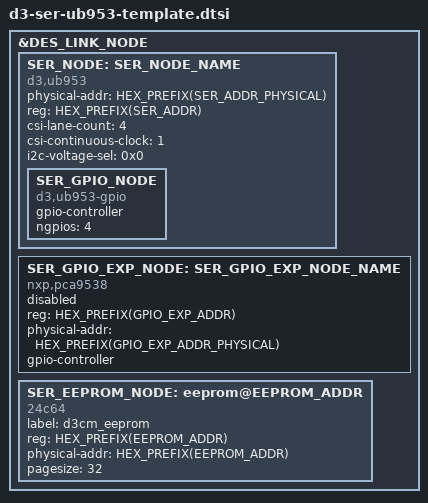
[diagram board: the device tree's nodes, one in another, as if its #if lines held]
/*
 * Copyright (c) 2019, D3 Engineering. All rights reserved.
 *
 * This program is free software; you can redistribute it and/or modify
 * it under the terms of the GNU General Public License as published by
 * the Free Software Foundation; version 2 of the License.
 *
 * This program is distributed in the hope that it will be useful, but WITHOUT
 * ANY WARRANTY; without even the implied warranty of MERCHANTABILITY or
 * FITNESS FOR A PARTICULAR PURPOSE.  See the GNU General Public License for
 * more details.
 */

#include "d3-reset-ser.dtsi"
#define SER_MODEL ub953
#define SER_ADDR_PHYSICAL 18
#define GPIO_EXP_ADDR_PHYSICAL 70
#include "d3-ser-common.dtsi"
#include "d3-check-ser-fpdlink.dtsi"

&DES_LINK_NODE {
	SER_NODE: SER_NODE_NAME {
		compatible = "d3,ub953";
		status = STR(STATUS);
		physical-addr = <HEX_PREFIX(SER_ADDR_PHYSICAL)>;
		#address-cells = <1>;
		#size-cells = <0>;
		reg = <HEX_PREFIX(SER_ADDR)>;
		csi-lane-count = <4>;
		csi-continuous-clock = <1>;
		i2c-voltage-sel = <0x0>;


		SER_GPIO_NODE: SER_GPIO_NODE {
			compatible = "d3,ub953-gpio";
			status = "okay";
			gpio-controller;
			#gpio-cells = <2>;
			ngpios = <4>;
		};
	};

	SER_GPIO_EXP_NODE: SER_GPIO_EXP_NODE_NAME {
		reg = <HEX_PREFIX(GPIO_EXP_ADDR)>;
		compatible = "nxp,pca9538";
		status = "disabled";
		physical-addr = <HEX_PREFIX(GPIO_EXP_ADDR_PHYSICAL)>;
		gpio-controller;
		#gpio-cells = <2>;
	};

#ifdef EEPROM_ADDR
	SER_EEPROM_NODE: eeprom@EEPROM_ADDR {
		status = STR(STATUS);
		compatible = "24c64";
		label = "d3cm_eeprom";
		reg = <HEX_PREFIX(EEPROM_ADDR)>;
		physical-addr = <HEX_PREFIX(EEPROM_ADDR)>;
		pagesize = <32>;
	};
#endif
};
